AUTOSAR XML (schema 00050)
package /ComponentTypes
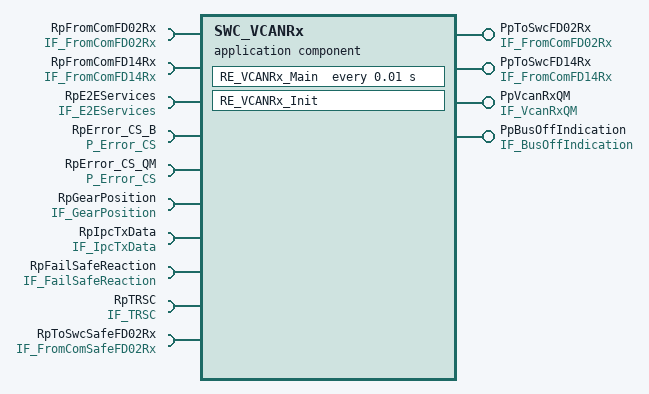
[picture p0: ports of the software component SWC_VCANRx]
  application sw component type SWC_VCANRx
    require port RpFromComFD02Rx: required-interface=IF_FromComFD02Rx
      required-com-specs:
        data-element=Altitude_RMSE_C2, init-value=255
        data-element=Battery_Volt_1, init-value=0
        data-element=BSM_THA_Brk_Resp, enable-update=true, init-value=0
        data-element=CurrentCanNMState_FD01_BCM, init-value=0
        data-element=CurrentCanNMState_FD01_SGW, init-value=0
        data-element=CurrentCanNMState_FD02_BCM, init-value=0
        data-element=CurrentCanNMState_FD02_BSM2, init-value=0
        data-element=CurrentCanNMState_FD02_CADM2, init-value=0
        data-element=CurrentCanNMState_FD02_EPS, init-value=0
        data-element=CurrentCanNMState_FD02_ORC, init-value=0
        data-element=CurrentCanNMState_FD02_SGW, init-value=0
        data-element=CurrentCanNMState_FD02_TRLR_REV, init-value=0
        data-element=CurrentCanNMState_FD03_BCM, init-value=0
        data-element=CurrentCanNMState_FD03_SGW, init-value=0
        data-element=CurrentCanNMState_FD04_BCM, init-value=0
        data-element=CurrentCanNMState_FD08_SGW, init-value=0
        data-element=CurrentCanNMState_FD11_SGW, init-value=0
        data-element=CurrentFailSts_FD01_BCM, init-value=0
        data-element=CurrentFailSts_FD01_SGW, init-value=0
        data-element=CurrentFailSts_FD02_BCM, init-value=0
        data-element=CurrentFailSts_FD02_BSM2, init-value=0
        data-element=CurrentFailSts_FD02_CADM2, init-value=0
        data-element=CurrentFailSts_FD02_EPS, init-value=0
        data-element=CurrentFailSts_FD02_ORC, init-value=0
        data-element=CurrentFailSts_FD02_SGW, init-value=0
        data-element=CurrentFailSts_FD02_TRLR_REV, init-value=0
        data-element=CurrentFailSts_FD03_BCM, init-value=0
        data-element=CurrentFailSts_FD03_SGW, init-value=0
        data-element=CurrentFailSts_FD04_BCM, init-value=0
        data-element=CurrentFailSts_FD08_SGW, init-value=0
        data-element=CurrentFailSts_FD11_SGW, init-value=0
        data-element=DeltaTimestamp_IMUdata, init-value=255
        data-element=DES_FD01_BCM, init-value=0
        data-element=DES_FD01_SGW, init-value=0
        data-element=DES_FD02_BCM, init-value=0
        data-element=DES_FD02_BSM2, init-value=0
        data-element=DES_FD02_CADM2, init-value=0
        data-element=DES_FD02_EPS, init-value=0
        data-element=DES_FD02_ORC, init-value=0
        data-element=DES_FD02_SGW, init-value=0
        data-element=DES_FD02_TRLR_REV, init-value=0
        data-element=DES_FD03_BCM, init-value=0
        data-element=DES_FD03_SGW, init-value=0
        data-element=DES_FD04_BCM, init-value=0
        data-element=DES_FD08_SGW, init-value=0
        data-element=DES_FD11_SGW, init-value=0
        data-element=Digit_{01..11}, init-value=0
        data-element=EOL_FD01_BCM, init-value=0
        data-element=EOL_FD01_SGW, init-value=0
        data-element=EOL_FD02_BCM, init-value=0
        data-element=EOL_FD02_BSM2, init-value=0
        data-element=EOL_FD02_CADM2, init-value=0
        data-element=EOL_FD02_EPS, init-value=0
        data-element=EOL_FD02_ORC, init-value=0
        data-element=EOL_FD02_SGW, init-value=0
        data-element=EOL_FD02_TRLR_REV, init-value=0
        data-element=EOL_FD03_BCM, init-value=0
        data-element=EOL_FD03_SGW, init-value=0
        data-element=EOL_FD04_BCM, init-value=0
        data-element=EOL_FD08_SGW, init-value=0
        data-element=EOL_FD11_SGW, init-value=0
        data-element=EPBSts, enable-update=true, init-value=0
        data-element=GenericFailSts_FD01_BCM, init-value=0
        data-element=GenericFailSts_FD01_SGW, init-value=0
        data-element=GenericFailSts_FD02_BCM, init-value=0
        data-element=GenericFailSts_FD02_BSM2, init-value=0
        data-element=GenericFailSts_FD02_CADM2, init-value=0
        data-element=GenericFailSts_FD02_EPS, init-value=0
        data-element=GenericFailSts_FD02_ORC, init-value=0
        data-element=GenericFailSts_FD02_SGW, init-value=0
        data-element=GenericFailSts_FD02_TRLR_REV, init-value=0
        data-element=GenericFailSts_FD03_BCM, init-value=0
        data-element=GenericFailSts_FD03_SGW, init-value=0
        data-element=GenericFailSts_FD04_BCM, init-value=0
        data-element=GenericFailSts_FD08_SGW, init-value=0
        data-element=GenericFailSts_FD11_SGW, init-value=0
        data-element=Heading_Angle_C2, init-value=65535
        data-element=IgnitionOnCounter, init-value=0
        data-element=LatAcceleration_C2, init-value=4095
        data-element=LatAccelerationOffset_BSM, init-value=255
        data-element=Latitude_RMSE_C2, init-value=255
        data-element=LHF_FastPulseCounter, init-value=0
        data-element=LHF_Spin, init-value=0
        data-element=LHFWheelSpeed, init-value=0
        data-element=LHR_FastPulseCounter, init-value=0
        data-element=LHR_Spin, init-value=0
        data-element=LHRWheelSpeed, init-value=0
        data-element=LongAcceleration_C2, init-value=4095
        data-element=LongAccelerationOffset_BSM, init-value=255
        data-element=Longitude_RMSE_C2, init-value=255
        data-element=OperationalModeSts, init-value=0
        data-element=Pitch_RMSE_C2, init-value=255
        data-element=PitchRate_C2, init-value=4095
        data-element=PreviousCanNMState_FD01_BCM, init-value=0
        data-element=PreviousCanNMState_FD01_SGW, init-value=0
        data-element=PreviousCanNMState_FD02_BCM, init-value=0
        data-element=PreviousCanNMState_FD02_BSM2, init-value=0
        data-element=PreviousCanNMState_FD02_CADM2, init-value=0
        data-element=PreviousCanNMState_FD02_EPS, init-value=0
        data-element=PreviousCanNMState_FD02_ORC, init-value=0
        data-element=PreviousCanNMState_FD02_SGW, init-value=0
        data-element=PreviousCanNMState_FD02_TRLR_REV, init-value=0
        data-element=PreviousCanNMState_FD03_BCM, init-value=0
        data-element=PreviousCanNMState_FD03_SGW, init-value=0
        data-element=PreviousCanNMState_FD04_BCM, init-value=0
        data-element=PreviousCanNMState_FD08_SGW, init-value=0
        data-element=PreviousCanNMState_FD11_SGW, init-value=0
        data-element=REF_VEH_SPEED, init-value=1023
        data-element=RemStActvSts, init-value=0
        data-element=RHF_FastPulseCounter, init-value=0
        data-element=RHF_Spin, init-value=0
        data-element=RHFWheelSpeed, init-value=0
        data-element=RHR_FastPulseCounter, init-value=0
        data-element=RHR_Spin, init-value=0
        data-element=RHRWheelSpeed, init-value=0
        data-element=Roll_RMSE_C2, init-value=255
        data-element=RollRate_C2, init-value=4095
        data-element=SBR1RowDriverSeatSts, enable-update=true, init-value=3
        data-element=StayActiveSource_FD01_BCM, init-value=0
        data-element=StayActiveSource_FD01_SGW, init-value=0
        data-element=StayActiveSource_FD02_BCM, init-value=0
        data-element=StayActiveSource_FD02_BSM2, init-value=0
        data-element=StayActiveSource_FD02_CADM2, init-value=0
        data-element=StayActiveSource_FD02_EPS, init-value=0
        data-element=StayActiveSource_FD02_ORC, init-value=0
        data-element=StayActiveSource_FD02_SGW, init-value=0
        data-element=StayActiveSource_FD02_TRLR_REV, init-value=0
        data-element=StayActiveSource_FD03_BCM, init-value=0
        data-element=StayActiveSource_FD03_SGW, init-value=0
        data-element=StayActiveSource_FD04_BCM, init-value=0
        data-element=StayActiveSource_FD08_SGW, init-value=0
        data-element=StayActiveSource_FD11_SGW, init-value=0
        data-element=TotalOdometer, init-value=0
        data-element=TRSC_CenterBtn_Sts, enable-update=true, init-value=0
        data-element=TRSC_EnableBtn_Sts, enable-update=true, init-value=0
        data-element=TRSC_RawKnob, enable-update=true, init-value=0
        data-element=TurnIndicatorSts, init-value=0
        data-element=VehicleStandStillSts, init-value=1
        data-element=VerticalAcceleration_C2, init-value=4095
        data-element=WakeupSource_FD01_ADCM, init-value=0
        data-element=WakeupSource_FD01_BCM, init-value=0
        data-element=WakeupSource_FD01_SGW, init-value=0
        data-element=WakeupSource_FD02_BCM, init-value=0
        data-element=WakeupSource_FD02_BSM2, init-value=0
        data-element=WakeupSource_FD02_CADM2, init-value=0
        data-element=WakeupSource_FD02_EPS, init-value=0
        data-element=WakeupSource_FD02_ORC, init-value=0
        data-element=WakeupSource_FD02_SGW, init-value=0
        data-element=WakeupSource_FD02_TRLR_REV, init-value=0
        data-element=WakeupSource_FD03_BCM, init-value=0
        data-element=WakeupSource_FD03_SGW, init-value=0
        data-element=WakeupSource_FD04_BCM, init-value=0
        data-element=WakeupSource_FD08_SGW, init-value=0
        data-element=WakeupSource_FD11_SGW, init-value=0
        data-element=YawRate_C2, init-value=4095
        data-element=YawRate_RMSE_C2, init-value=255
    require port RpFromComFD14Rx: required-interface=IF_FromComFD14Rx
      required-com-specs:
        data-element=FD14_Accel_Pedal_Override, init-value=0
        data-element=FD14_DriverReq_AxleTrq_Enabled_BSM, init-value=0
        data-element=FD14_PPPA_TrqEnblRq_Allowed, init-value=0
    provide port PpToSwcFD02Rx: provided-interface=IF_FromComFD02Rx
      provided-com-specs:
        data-element=Altitude_RMSE_C2, init-value=255
        data-element=Battery_Volt_1, init-value=0
        data-element=BSM_THA_Brk_Resp, init-value=0
        data-element=CurrentCanNMState_FD01_BCM, init-value=0
        data-element=CurrentCanNMState_FD01_SGW, init-value=0
        data-element=CurrentCanNMState_FD02_BCM, init-value=0
        data-element=CurrentCanNMState_FD02_BSM2, init-value=0
        data-element=CurrentCanNMState_FD02_CADM2, init-value=0
        data-element=CurrentCanNMState_FD02_EPS, init-value=0
        data-element=CurrentCanNMState_FD02_ORC, init-value=0
        data-element=CurrentCanNMState_FD02_SGW, init-value=0
        data-element=CurrentCanNMState_FD02_TRLR_REV, init-value=0
        data-element=CurrentCanNMState_FD03_BCM, init-value=0
        data-element=CurrentCanNMState_FD03_SGW, init-value=0
        data-element=CurrentCanNMState_FD04_BCM, init-value=0
        data-element=CurrentCanNMState_FD08_SGW, init-value=0
        data-element=CurrentCanNMState_FD11_SGW, init-value=0
        data-element=CurrentFailSts_FD01_BCM, init-value=0
        data-element=CurrentFailSts_FD01_SGW, init-value=0
        data-element=CurrentFailSts_FD02_BCM, init-value=0
        data-element=CurrentFailSts_FD02_BSM2, init-value=0
        data-element=CurrentFailSts_FD02_CADM2, init-value=0
        data-element=CurrentFailSts_FD02_EPS, init-value=0
        data-element=CurrentFailSts_FD02_ORC, init-value=0
        data-element=CurrentFailSts_FD02_SGW, init-value=0
        data-element=CurrentFailSts_FD02_TRLR_REV, init-value=0
        data-element=CurrentFailSts_FD03_BCM, init-value=0
        data-element=CurrentFailSts_FD03_SGW, init-value=0
        data-element=CurrentFailSts_FD04_BCM, init-value=0
        data-element=CurrentFailSts_FD08_SGW, init-value=0
        data-element=CurrentFailSts_FD11_SGW, init-value=0
        data-element=DeltaTimestamp_IMUdata, init-value=255
        data-element=DES_FD01_BCM, init-value=0
        data-element=DES_FD01_SGW, init-value=0
        data-element=DES_FD02_BCM, init-value=0
        data-element=DES_FD02_BSM2, init-value=0
        data-element=DES_FD02_CADM2, init-value=0
        data-element=DES_FD02_EPS, init-value=0
        data-element=DES_FD02_ORC, init-value=0
        data-element=DES_FD02_SGW, init-value=0
        data-element=DES_FD02_TRLR_REV, init-value=0
        data-element=DES_FD03_BCM, init-value=0
        data-element=DES_FD03_SGW, init-value=0
        data-element=DES_FD04_BCM, init-value=0
        data-element=DES_FD08_SGW, init-value=0
        data-element=DES_FD11_SGW, init-value=0
        data-element=Digit_{01..11}, init-value=0
        data-element=EOL_FD01_BCM, init-value=0
        data-element=EOL_FD01_SGW, init-value=0
        data-element=EOL_FD02_BCM, init-value=0
        data-element=EOL_FD02_BSM2, init-value=0
        data-element=EOL_FD02_CADM2, init-value=0
        data-element=EOL_FD02_EPS, init-value=0
        data-element=EOL_FD02_ORC, init-value=0
        data-element=EOL_FD02_SGW, init-value=0
        data-element=EOL_FD02_TRLR_REV, init-value=0
        data-element=EOL_FD03_BCM, init-value=0
        data-element=EOL_FD03_SGW, init-value=0
        data-element=EOL_FD04_BCM, init-value=0
        data-element=EOL_FD08_SGW, init-value=0
        data-element=EOL_FD11_SGW, init-value=0
        data-element=EPBSts, init-value=0
        data-element=GenericFailSts_FD01_BCM, init-value=0
        data-element=GenericFailSts_FD01_SGW, init-value=0
        data-element=GenericFailSts_FD02_BCM, init-value=0
        data-element=GenericFailSts_FD02_BSM2, init-value=0
        data-element=GenericFailSts_FD02_CADM2, init-value=0
        data-element=GenericFailSts_FD02_EPS, init-value=0
        data-element=GenericFailSts_FD02_ORC, init-value=0
        data-element=GenericFailSts_FD02_SGW, init-value=0
        data-element=GenericFailSts_FD02_TRLR_REV, init-value=0
        data-element=GenericFailSts_FD03_BCM, init-value=0
        data-element=GenericFailSts_FD03_SGW, init-value=0
        data-element=GenericFailSts_FD04_BCM, init-value=0
        data-element=GenericFailSts_FD08_SGW, init-value=0
        data-element=GenericFailSts_FD11_SGW, init-value=0
        data-element=Heading_Angle_C2, init-value=65535
        data-element=IgnitionOnCounter, init-value=0
        data-element=LatAcceleration_C2, init-value=4095
        data-element=LatAccelerationOffset_BSM, init-value=255
        data-element=Latitude_RMSE_C2, init-value=255
        data-element=LHF_FastPulseCounter, init-value=0
        data-element=LHF_Spin, init-value=0
        data-element=LHFWheelSpeed, init-value=0
        data-element=LHR_FastPulseCounter, init-value=0
        data-element=LHR_Spin, init-value=0
        data-element=LHRWheelSpeed, init-value=0
        data-element=LongAcceleration_C2, init-value=4095
        data-element=LongAccelerationOffset_BSM, init-value=255
        data-element=Longitude_RMSE_C2, init-value=255
        data-element=OperationalModeSts, init-value=0
        data-element=Pitch_RMSE_C2, init-value=255
        data-element=PitchRate_C2, init-value=4095
        data-element=PreviousCanNMState_FD01_BCM, init-value=0
        data-element=PreviousCanNMState_FD01_SGW, init-value=0
        data-element=PreviousCanNMState_FD02_BCM, init-value=0
        data-element=PreviousCanNMState_FD02_BSM2, init-value=0
        data-element=PreviousCanNMState_FD02_CADM2, init-value=0
        data-element=PreviousCanNMState_FD02_EPS, init-value=0
        data-element=PreviousCanNMState_FD02_ORC, init-value=0
        data-element=PreviousCanNMState_FD02_SGW, init-value=0
        data-element=PreviousCanNMState_FD02_TRLR_REV, init-value=0
        data-element=PreviousCanNMState_FD03_BCM, init-value=0
        data-element=PreviousCanNMState_FD03_SGW, init-value=0
        data-element=PreviousCanNMState_FD04_BCM, init-value=0
        data-element=PreviousCanNMState_FD08_SGW, init-value=0
        data-element=PreviousCanNMState_FD11_SGW, init-value=0
        data-element=REF_VEH_SPEED, init-value=1023
        data-element=RemStActvSts, init-value=0
        data-element=RHF_FastPulseCounter, init-value=0
        data-element=RHF_Spin, init-value=0
        data-element=RHFWheelSpeed, init-value=0
        data-element=RHR_FastPulseCounter, init-value=0
        data-element=RHR_Spin, init-value=0
        data-element=RHRWheelSpeed, init-value=0
        data-element=Roll_RMSE_C2, init-value=255
        data-element=RollRate_C2, init-value=4095
        data-element=SBR1RowDriverSeatSts, init-value=3
        data-element=StayActiveSource_FD01_BCM, init-value=0
        data-element=StayActiveSource_FD01_SGW, init-value=0
        data-element=StayActiveSource_FD02_BCM, init-value=0
        data-element=StayActiveSource_FD02_BSM2, init-value=0
        data-element=StayActiveSource_FD02_CADM2, init-value=0
        data-element=StayActiveSource_FD02_EPS, init-value=0
        data-element=StayActiveSource_FD02_ORC, init-value=0
        data-element=StayActiveSource_FD02_SGW, init-value=0
        data-element=StayActiveSource_FD02_TRLR_REV, init-value=0
        data-element=StayActiveSource_FD03_BCM, init-value=0
        data-element=StayActiveSource_FD03_SGW, init-value=0
        data-element=StayActiveSource_FD04_BCM, init-value=0
        data-element=StayActiveSource_FD08_SGW, init-value=0
        data-element=StayActiveSource_FD11_SGW, init-value=0
        data-element=TotalOdometer, init-value=0
        data-element=TRSC_CenterBtn_Sts, init-value=0
        data-element=TRSC_EnableBtn_Sts, init-value=0
        data-element=TRSC_RawKnob, init-value=0
        data-element=TurnIndicatorSts, init-value=0
        data-element=VehicleStandStillSts, init-value=1
        data-element=VerticalAcceleration_C2, init-value=4095
        data-element=WakeupSource_FD01_ADCM, init-value=0
        data-element=WakeupSource_FD01_BCM, init-value=0
        data-element=WakeupSource_FD01_SGW, init-value=0
        data-element=WakeupSource_FD02_BCM, init-value=0
        data-element=WakeupSource_FD02_BSM2, init-value=0
        data-element=WakeupSource_FD02_CADM2, init-value=0
        data-element=WakeupSource_FD02_EPS, init-value=0
        data-element=WakeupSource_FD02_ORC, init-value=0
        data-element=WakeupSource_FD02_SGW, init-value=0
        data-element=WakeupSource_FD02_TRLR_REV, init-value=0
        data-element=WakeupSource_FD03_BCM, init-value=0
        data-element=WakeupSource_FD03_SGW, init-value=0
        data-element=WakeupSource_FD04_BCM, init-value=0
        data-element=WakeupSource_FD08_SGW, init-value=0
        data-element=WakeupSource_FD11_SGW, init-value=0
        data-element=YawRate_C2, init-value=4095
        data-element=YawRate_RMSE_C2, init-value=255
    provide port PpToSwcFD14Rx: provided-interface=IF_FromComFD14Rx
      provided-com-specs:
        data-element=FD14_Accel_Pedal_Override, init-value=0
        data-element=FD14_DriverReq_AxleTrq_Enabled_BSM, init-value=0
        data-element=FD14_PPPA_TrqEnblRq_Allowed, init-value=0
    6 x require port:
      RpE2EServices: required-com-specs=[ME_E2E_Check, ME_E2E_Protect], required-interface=IF_E2EServices
      RpError_CS_B: client-com-spec=ReportErrorStatus1_0_B, required-interface=P_Error_CS
      RpError_CS_QM: client-com-spec=ReportErrorStatus1_0_QM, required-interface=P_Error_CS
      RpGearPosition: required-interface=IF_GearPosition
        required-com-specs:
          data-element=GearValue, filter=data-filter-type=ALWAYS, init-value=0
          data-element=ShortTermAdjActiveFlag_b, filter=data-filter-type=ALWAYS
      RpIpcTxData: client-com-spec=IPC_Write_v, required-interface=IF_IpcTxData
      RpFailSafeReaction: nonqueued-receiver-com-spec{data-element=State, filter=data-filter-type=ALWAYS, init-value=0}, required-interface=IF_FailSafeReaction
    provide port PpVcanRxQM: nonqueued-sender-com-spec{data-element=ME_VehInp_to_IpcSignals_QM_t, init-value=fields=[{short-label=DataInp_BCM_FD_2, fields=[RemStActvSts:0, TurnIndicatorSts:0]}, {short-label=DataInp_BCM_FD_21, fields=Snow_Plow_Presence:0}, {short-label=DataInp_TRSKM_FD_1, fields=[TRSC_CenterBtn_Sts:0, TRSC_EnableBtn_Sts:0, TRSC_RawKnob:0]}, {short-label=DataInp_FD14_BRAKE_FD_6, fields=FD14_DriverReq_AxleTrq_Enabled_BSM:0}, {short-label=DataInp_ORC_FD_1, fields=SBR1RowDriverSeatSts:0}, {short-label=DataInp_FD14_PT_TORQUE_FD_1, fields=[FD14_Accel_Pedal_Override:0, FD14_PPPA_TrqEnblRq_Allowed:0]}]}, provided-interface=IF_VcanRxQM
    provide port PpBusOffIndication: nonqueued-sender-com-spec{data-element=V_BusOffIndicationFlagRte_u8, init-value=0}, provided-interface=IF_BusOffIndication
    require port RpTRSC: nonqueued-receiver-com-spec=data-element=ME_VehOut_TRSC_t, required-interface=IF_TRSC
    require port RpToSwcSafeFD02Rx: required-interface=IF_FromComSafeFD02Rx
      required-com-specs:
        data-element=YawRate_BSM, filter=data-filter-type=ALWAYS
        data-element=VehicleSpeedVSOSig, filter=data-filter-type=ALWAYS
        data-element=TransmissionSailingSts, filter=data-filter-type=ALWAYS
        data-element=TRANS_ADAS_Inhibit, filter=data-filter-type=ALWAYS
        data-element=TrailerConnectionSts, filter=data-filter-type=ALWAYS
        data-element=TGW_CAMERA_DISP_STAT, filter=data-filter-type=ALWAYS
        data-element=TCASERANGESTATUS, filter=data-filter-type=ALWAYS
        data-element=TargetGear, filter=data-filter-type=ALWAYS
        data-element=SVC_Guidelines, filter=data-filter-type=ALWAYS
        data-element=ShiftLeverPosition, filter=data-filter-type=ALWAYS
        data-element=RHRDoorSts, filter=data-filter-type=ALWAYS
        data-element=RHatchSts, filter=data-filter-type=ALWAYS
        data-element=Rear_Brk_Asst, filter=data-filter-type=ALWAYS
        data-element=PsngrDoorSts, filter=data-filter-type=ALWAYS
        data-element=PAMRequestSts, filter=data-filter-type=ALWAYS
        data-element=PamChimeVolumeRear, filter=data-filter-type=ALWAYS
        data-element=PamChimeVolumeFront, filter=data-filter-type=ALWAYS
        data-element=MRM_STATUS_C2, filter=data-filter-type=ALWAYS
        data-element=LwsSpeed, filter=data-filter-type=ALWAYS
        data-element=LwsAngleType, filter=data-filter-type=ALWAYS
        data-element=LwsAngle, filter=data-filter-type=ALWAYS
        data-element=LongAcceleration_BSM, filter=data-filter-type=ALWAYS
        data-element=LHRDoorSts, filter=data-filter-type=ALWAYS
        data-element=LatAcceleration_BSM, filter=data-filter-type=ALWAYS
        data-element=LanguageSelection, filter=data-filter-type=ALWAYS
        data-element=HAS_Status_C2, filter=data-filter-type=ALWAYS
        data-element=GearEngaged, filter=data-filter-type=ALWAYS
        data-element=Fwrd_Cam_Guidelines, filter=data-filter-type=ALWAYS
        data-element=FT_PAMRequestSts, filter=data-filter-type=ALWAYS
        data-element=ExternalTemperature, filter=data-filter-type=ALWAYS
        data-element=DynamicGrid, filter=data-filter-type=ALWAYS
        data-element=DriverDoorSts, filter=data-filter-type=ALWAYS
        data-element=CmdIgnSts, filter=data-filter-type=ALWAYS
        data-element=Brk_Stat, filter=data-filter-type=ALWAYS
        data-element=Backup_Cam_Delay, filter=data-filter-type=ALWAYS
        data-element=APARequestSts, filter=data-filter-type=ALWAYS
        data-element=Active_Park_Prox_Chime, filter=data-filter-type=ALWAYS
        data-element=Active_Park_Mode, filter=data-filter-type=ALWAYS
        data-element=VIN_MSG, filter=data-filter-type=ALWAYS
        data-element=VIN_DATA, filter=data-filter-type=ALWAYS
        data-element=RR_Lvl_Adj, filter=data-filter-type=ALWAYS
        data-element=RR_Lvl, filter=data-filter-type=ALWAYS
        data-element=RL_Lvl_Adj, filter=data-filter-type=ALWAYS
        data-element=RL_Lvl, filter=data-filter-type=ALWAYS
        data-element=HU_TRSC_EnableBtn_Sts, filter=data-filter-type=ALWAYS
        data-element=GearEngagedForDisplay, filter=data-filter-type=ALWAYS
        data-element=FR_Lvl_Adj, filter=data-filter-type=ALWAYS
        data-element=FR_Lvl, filter=data-filter-type=ALWAYS
        data-element=FL_Lvl_Adj, filter=data-filter-type=ALWAYS
        data-element=FL_Lvl, filter=data-filter-type=ALWAYS
        data-element=ESS_ENG_ST_W, filter=data-filter-type=ALWAYS
        data-element=EngineSts_W, filter=data-filter-type=ALWAYS
        data-element=ECM_TRSC_Resp, filter=data-filter-type=ALWAYS
        data-element=ECM_THA_Resp, filter=data-filter-type=ALWAYS
        data-element=ASCM_SysFail, filter=data-filter-type=ALWAYS
        data-element=ASCM_Stat, filter=data-filter-type=ALWAYS
        data-element=PdlPosActual, filter=data-filter-type=ALWAYS
        data-element=THA_SteeringTouchStat, filter=data-filter-type=ALWAYS
        data-element=EPS_THA_SteeringTorqueResp, filter=data-filter-type=ALWAYS
        data-element=EPS_THA_DriverTorqueOverride, filter=data-filter-type=ALWAYS
        data-element=EPS_SteeringTouq_Resp, filter=data-filter-type=ALWAYS
        data-element=EPS_SteeringTouchStat, filter=data-filter-type=ALWAYS
        data-element=ShiftLeverPositionReq, filter=data-filter-type=ALWAYS
        data-element=Shifter_ADAS_Inhibit, filter=data-filter-type=ALWAYS
        data-element=ITBM_TrlrStat, filter=data-filter-type=ALWAYS
        data-element=CM_TCH_Y_COORD, filter=data-filter-type=ALWAYS
        data-element=CM_TCH_X_COORD, filter=data-filter-type=ALWAYS
        data-element=CM_TCH_STAT, filter=data-filter-type=ALWAYS
        data-element=CameraDisplaySts2, filter=data-filter-type=ALWAYS
    behavior SWC_VCANRx_InternalBehavior: data-type-mapping=[defaultDataTypeMappingSet_CPFS, defaultDataTypeMappingSet_CPFS]
      init event SWC_VCANRx_InitEvent: start-on-event=RE_VCANRx_Init
      timing event TMT_RE_VCANRx_Main: start-on-event=RE_VCANRx_Main, period=0.01
      runnable RE_VCANRx_Init
      runnable RE_VCANRx_Main
        data-receive-point-by-arguments:
          175 x access:
            REC_RpFailSafeReaction_State: accessed-variable=RpFailSafeReaction.State
            REC_RpFromComFD02Rx_Altitude_RMSE_C2: accessed-variable=RpFromComFD02Rx.Altitude_RMSE_C2
            REC_RpFromComFD02Rx_BSM_THA_Brk_Resp: accessed-variable=RpFromComFD02Rx.BSM_THA_Brk_Resp
            REC_RpFromComFD02Rx_Battery_Volt_1: accessed-variable=RpFromComFD02Rx.Battery_Volt_1
            REC_RpFromComFD02Rx_CurrentCanNMState_FD01_BCM: accessed-variable=RpFromComFD02Rx.CurrentCanNMState_FD01_BCM
            REC_RpFromComFD02Rx_CurrentCanNMState_FD01_SGW: accessed-variable=RpFromComFD02Rx.CurrentCanNMState_FD01_SGW
            REC_RpFromComFD02Rx_CurrentCanNMState_FD02_BCM: accessed-variable=RpFromComFD02Rx.CurrentCanNMState_FD02_BCM
            REC_RpFromComFD02Rx_CurrentCanNMState_FD02_BSM2: accessed-variable=RpFromComFD02Rx.CurrentCanNMState_FD02_BSM2
            REC_RpFromComFD02Rx_CurrentCanNMState_FD02_CADM2: accessed-variable=RpFromComFD02Rx.CurrentCanNMState_FD02_CADM2
            REC_RpFromComFD02Rx_CurrentCanNMState_FD02_EPS: accessed-variable=RpFromComFD02Rx.CurrentCanNMState_FD02_EPS
            REC_RpFromComFD02Rx_CurrentCanNMState_FD02_ORC: accessed-variable=RpFromComFD02Rx.CurrentCanNMState_FD02_ORC
            REC_RpFromComFD02Rx_CurrentCanNMState_FD02_SGW: accessed-variable=RpFromComFD02Rx.CurrentCanNMState_FD02_SGW
            REC_RpFromComFD02Rx_CurrentCanNMState_FD02_TRLR_REV: accessed-variable=RpFromComFD02Rx.CurrentCanNMState_FD02_TRLR_REV
            REC_RpFromComFD02Rx_CurrentCanNMState_FD03_BCM: accessed-variable=RpFromComFD02Rx.CurrentCanNMState_FD03_BCM
            REC_RpFromComFD02Rx_CurrentCanNMState_FD03_SGW: accessed-variable=RpFromComFD02Rx.CurrentCanNMState_FD03_SGW
            REC_RpFromComFD02Rx_CurrentCanNMState_FD04_BCM: accessed-variable=RpFromComFD02Rx.CurrentCanNMState_FD04_BCM
            REC_RpFromComFD02Rx_CurrentCanNMState_FD08_SGW: accessed-variable=RpFromComFD02Rx.CurrentCanNMState_FD08_SGW
            REC_RpFromComFD02Rx_CurrentCanNMState_FD11_SGW: accessed-variable=RpFromComFD02Rx.CurrentCanNMState_FD11_SGW
            REC_RpFromComFD02Rx_CurrentFailSts_FD01_BCM: accessed-variable=RpFromComFD02Rx.CurrentFailSts_FD01_BCM
            REC_RpFromComFD02Rx_CurrentFailSts_FD01_SGW: accessed-variable=RpFromComFD02Rx.CurrentFailSts_FD01_SGW
            REC_RpFromComFD02Rx_CurrentFailSts_FD02_BCM: accessed-variable=RpFromComFD02Rx.CurrentFailSts_FD02_BCM
            REC_RpFromComFD02Rx_CurrentFailSts_FD02_BSM2: accessed-variable=RpFromComFD02Rx.CurrentFailSts_FD02_BSM2
            REC_RpFromComFD02Rx_CurrentFailSts_FD02_CADM2: accessed-variable=RpFromComFD02Rx.CurrentFailSts_FD02_CADM2
            REC_RpFromComFD02Rx_CurrentFailSts_FD02_EPS: accessed-variable=RpFromComFD02Rx.CurrentFailSts_FD02_EPS
            REC_RpFromComFD02Rx_CurrentFailSts_FD02_ORC: accessed-variable=RpFromComFD02Rx.CurrentFailSts_FD02_ORC
            REC_RpFromComFD02Rx_CurrentFailSts_FD02_SGW: accessed-variable=RpFromComFD02Rx.CurrentFailSts_FD02_SGW
            REC_RpFromComFD02Rx_CurrentFailSts_FD02_TRLR_REV: accessed-variable=RpFromComFD02Rx.CurrentFailSts_FD02_TRLR_REV
            REC_RpFromComFD02Rx_CurrentFailSts_FD03_BCM: accessed-variable=RpFromComFD02Rx.CurrentFailSts_FD03_BCM
            REC_RpFromComFD02Rx_CurrentFailSts_FD03_SGW: accessed-variable=RpFromComFD02Rx.CurrentFailSts_FD03_SGW
            REC_RpFromComFD02Rx_CurrentFailSts_FD04_BCM: accessed-variable=RpFromComFD02Rx.CurrentFailSts_FD04_BCM
            REC_RpFromComFD02Rx_CurrentFailSts_FD08_SGW: accessed-variable=RpFromComFD02Rx.CurrentFailSts_FD08_SGW
            REC_RpFromComFD02Rx_CurrentFailSts_FD11_SGW: accessed-variable=RpFromComFD02Rx.CurrentFailSts_FD11_SGW
            REC_RpFromComFD02Rx_DES_FD01_BCM: accessed-variable=RpFromComFD02Rx.DES_FD01_BCM
            REC_RpFromComFD02Rx_DES_FD01_SGW: accessed-variable=RpFromComFD02Rx.DES_FD01_SGW
            REC_RpFromComFD02Rx_DES_FD02_BCM: accessed-variable=RpFromComFD02Rx.DES_FD02_BCM
            REC_RpFromComFD02Rx_DES_FD02_BSM2: accessed-variable=RpFromComFD02Rx.DES_FD02_BSM2
            REC_RpFromComFD02Rx_DES_FD02_CADM2: accessed-variable=RpFromComFD02Rx.DES_FD02_CADM2
            REC_RpFromComFD02Rx_DES_FD02_EPS: accessed-variable=RpFromComFD02Rx.DES_FD02_EPS
            REC_RpFromComFD02Rx_DES_FD02_ORC: accessed-variable=RpFromComFD02Rx.DES_FD02_ORC
            REC_RpFromComFD02Rx_DES_FD02_SGW: accessed-variable=RpFromComFD02Rx.DES_FD02_SGW
            REC_RpFromComFD02Rx_DES_FD02_TRLR_REV: accessed-variable=RpFromComFD02Rx.DES_FD02_TRLR_REV
            REC_RpFromComFD02Rx_DES_FD03_BCM: accessed-variable=RpFromComFD02Rx.DES_FD03_BCM
            REC_RpFromComFD02Rx_DES_FD03_SGW: accessed-variable=RpFromComFD02Rx.DES_FD03_SGW
            REC_RpFromComFD02Rx_DES_FD04_BCM: accessed-variable=RpFromComFD02Rx.DES_FD04_BCM
            REC_RpFromComFD02Rx_DES_FD08_SGW: accessed-variable=RpFromComFD02Rx.DES_FD08_SGW
            REC_RpFromComFD02Rx_DES_FD11_SGW: accessed-variable=RpFromComFD02Rx.DES_FD11_SGW
            REC_RpFromComFD02Rx_DeltaTimestamp_IMUdata: accessed-variable=RpFromComFD02Rx.DeltaTimestamp_IMUdata
            REC_RpFromComFD02Rx_Digit_{01..11}: accessed-variable=RpFromComFD02Rx.Digit_{01..11}
            REC_RpFromComFD02Rx_EOL_FD01_BCM: accessed-variable=RpFromComFD02Rx.EOL_FD01_BCM
            REC_RpFromComFD02Rx_EOL_FD01_SGW: accessed-variable=RpFromComFD02Rx.EOL_FD01_SGW
            REC_RpFromComFD02Rx_EOL_FD02_BCM: accessed-variable=RpFromComFD02Rx.EOL_FD02_BCM
            REC_RpFromComFD02Rx_EOL_FD02_BSM2: accessed-variable=RpFromComFD02Rx.EOL_FD02_BSM2
            REC_RpFromComFD02Rx_EOL_FD02_CADM2: accessed-variable=RpFromComFD02Rx.EOL_FD02_CADM2
            REC_RpFromComFD02Rx_EOL_FD02_EPS: accessed-variable=RpFromComFD02Rx.EOL_FD02_EPS
            REC_RpFromComFD02Rx_EOL_FD02_ORC: accessed-variable=RpFromComFD02Rx.EOL_FD02_ORC
            REC_RpFromComFD02Rx_EOL_FD02_SGW: accessed-variable=RpFromComFD02Rx.EOL_FD02_SGW
            REC_RpFromComFD02Rx_EOL_FD02_TRLR_REV: accessed-variable=RpFromComFD02Rx.EOL_FD02_TRLR_REV
            REC_RpFromComFD02Rx_EOL_FD03_BCM: accessed-variable=RpFromComFD02Rx.EOL_FD03_BCM
            REC_RpFromComFD02Rx_EOL_FD03_SGW: accessed-variable=RpFromComFD02Rx.EOL_FD03_SGW
            REC_RpFromComFD02Rx_EOL_FD04_BCM: accessed-variable=RpFromComFD02Rx.EOL_FD04_BCM
            REC_RpFromComFD02Rx_EOL_FD08_SGW: accessed-variable=RpFromComFD02Rx.EOL_FD08_SGW
            REC_RpFromComFD02Rx_EOL_FD11_SGW: accessed-variable=RpFromComFD02Rx.EOL_FD11_SGW
            REC_RpFromComFD02Rx_EPBSts: accessed-variable=RpFromComFD02Rx.EPBSts
            REC_RpFromComFD02Rx_GenericFailSts_FD01_BCM: accessed-variable=RpFromComFD02Rx.GenericFailSts_FD01_BCM
            REC_RpFromComFD02Rx_GenericFailSts_FD01_SGW: accessed-variable=RpFromComFD02Rx.GenericFailSts_FD01_SGW
            REC_RpFromComFD02Rx_GenericFailSts_FD02_BCM: accessed-variable=RpFromComFD02Rx.GenericFailSts_FD02_BCM
            REC_RpFromComFD02Rx_GenericFailSts_FD02_BSM2: accessed-variable=RpFromComFD02Rx.GenericFailSts_FD02_BSM2
            REC_RpFromComFD02Rx_GenericFailSts_FD02_CADM2: accessed-variable=RpFromComFD02Rx.GenericFailSts_FD02_CADM2
            REC_RpFromComFD02Rx_GenericFailSts_FD02_EPS: accessed-variable=RpFromComFD02Rx.GenericFailSts_FD02_EPS
            REC_RpFromComFD02Rx_GenericFailSts_FD02_ORC: accessed-variable=RpFromComFD02Rx.GenericFailSts_FD02_ORC
            REC_RpFromComFD02Rx_GenericFailSts_FD02_SGW: accessed-variable=RpFromComFD02Rx.GenericFailSts_FD02_SGW
            REC_RpFromComFD02Rx_GenericFailSts_FD02_TRLR_REV: accessed-variable=RpFromComFD02Rx.GenericFailSts_FD02_TRLR_REV
            REC_RpFromComFD02Rx_GenericFailSts_FD03_BCM: accessed-variable=RpFromComFD02Rx.GenericFailSts_FD03_BCM
            REC_RpFromComFD02Rx_GenericFailSts_FD03_SGW: accessed-variable=RpFromComFD02Rx.GenericFailSts_FD03_SGW
            REC_RpFromComFD02Rx_GenericFailSts_FD04_BCM: accessed-variable=RpFromComFD02Rx.GenericFailSts_FD04_BCM
            REC_RpFromComFD02Rx_GenericFailSts_FD08_SGW: accessed-variable=RpFromComFD02Rx.GenericFailSts_FD08_SGW
            REC_RpFromComFD02Rx_GenericFailSts_FD11_SGW: accessed-variable=RpFromComFD02Rx.GenericFailSts_FD11_SGW
            REC_RpFromComFD02Rx_Heading_Angle_C2: accessed-variable=RpFromComFD02Rx.Heading_Angle_C2
            REC_RpFromComFD02Rx_IgnitionOnCounter: accessed-variable=RpFromComFD02Rx.IgnitionOnCounter
            REC_RpFromComFD02Rx_LHFWheelSpeed: accessed-variable=RpFromComFD02Rx.LHFWheelSpeed
            REC_RpFromComFD02Rx_LHF_FastPulseCounter: accessed-variable=RpFromComFD02Rx.LHF_FastPulseCounter
            REC_RpFromComFD02Rx_LHF_Spin: accessed-variable=RpFromComFD02Rx.LHF_Spin
            REC_RpFromComFD02Rx_LHRWheelSpeed: accessed-variable=RpFromComFD02Rx.LHRWheelSpeed
            REC_RpFromComFD02Rx_LHR_FastPulseCounter: accessed-variable=RpFromComFD02Rx.LHR_FastPulseCounter
            REC_RpFromComFD02Rx_LHR_Spin: accessed-variable=RpFromComFD02Rx.LHR_Spin
            REC_RpFromComFD02Rx_LatAccelerationOffset_BSM: accessed-variable=RpFromComFD02Rx.LatAccelerationOffset_BSM
            REC_RpFromComFD02Rx_LatAcceleration_C2: accessed-variable=RpFromComFD02Rx.LatAcceleration_C2
            REC_RpFromComFD02Rx_Latitude_RMSE_C2: accessed-variable=RpFromComFD02Rx.Latitude_RMSE_C2
            REC_RpFromComFD02Rx_LongAccelerationOffset_BSM: accessed-variable=RpFromComFD02Rx.LongAccelerationOffset_BSM
            REC_RpFromComFD02Rx_LongAcceleration_C2: accessed-variable=RpFromComFD02Rx.LongAcceleration_C2
            REC_RpFromComFD02Rx_Longitude_RMSE_C2: accessed-variable=RpFromComFD02Rx.Longitude_RMSE_C2
            REC_RpFromComFD02Rx_OperationalModeSts: accessed-variable=RpFromComFD02Rx.OperationalModeSts
            REC_RpFromComFD02Rx_PitchRate_C2: accessed-variable=RpFromComFD02Rx.PitchRate_C2
            REC_RpFromComFD02Rx_Pitch_RMSE_C2: accessed-variable=RpFromComFD02Rx.Pitch_RMSE_C2
            REC_RpFromComFD02Rx_PreviousCanNMState_FD01_BCM: accessed-variable=RpFromComFD02Rx.PreviousCanNMState_FD01_BCM
            REC_RpFromComFD02Rx_PreviousCanNMState_FD01_SGW: accessed-variable=RpFromComFD02Rx.PreviousCanNMState_FD01_SGW
            REC_RpFromComFD02Rx_PreviousCanNMState_FD02_BCM: accessed-variable=RpFromComFD02Rx.PreviousCanNMState_FD02_BCM
            REC_RpFromComFD02Rx_PreviousCanNMState_FD02_BSM2: accessed-variable=RpFromComFD02Rx.PreviousCanNMState_FD02_BSM2
            REC_RpFromComFD02Rx_PreviousCanNMState_FD02_CADM2: accessed-variable=RpFromComFD02Rx.PreviousCanNMState_FD02_CADM2
            REC_RpFromComFD02Rx_PreviousCanNMState_FD02_EPS: accessed-variable=RpFromComFD02Rx.PreviousCanNMState_FD02_EPS
            REC_RpFromComFD02Rx_PreviousCanNMState_FD02_ORC: accessed-variable=RpFromComFD02Rx.PreviousCanNMState_FD02_ORC
            REC_RpFromComFD02Rx_PreviousCanNMState_FD02_SGW: accessed-variable=RpFromComFD02Rx.PreviousCanNMState_FD02_SGW
            REC_RpFromComFD02Rx_PreviousCanNMState_FD02_TRLR_REV: accessed-variable=RpFromComFD02Rx.PreviousCanNMState_FD02_TRLR_REV
            REC_RpFromComFD02Rx_PreviousCanNMState_FD03_BCM: accessed-variable=RpFromComFD02Rx.PreviousCanNMState_FD03_BCM
            REC_RpFromComFD02Rx_PreviousCanNMState_FD03_SGW: accessed-variable=RpFromComFD02Rx.PreviousCanNMState_FD03_SGW
            REC_RpFromComFD02Rx_PreviousCanNMState_FD04_BCM: accessed-variable=RpFromComFD02Rx.PreviousCanNMState_FD04_BCM
            REC_RpFromComFD02Rx_PreviousCanNMState_FD08_SGW: accessed-variable=RpFromComFD02Rx.PreviousCanNMState_FD08_SGW
            REC_RpFromComFD02Rx_PreviousCanNMState_FD11_SGW: accessed-variable=RpFromComFD02Rx.PreviousCanNMState_FD11_SGW
            REC_RpFromComFD02Rx_REF_VEH_SPEED: accessed-variable=RpFromComFD02Rx.REF_VEH_SPEED
            REC_RpFromComFD02Rx_RHFWheelSpeed: accessed-variable=RpFromComFD02Rx.RHFWheelSpeed
            REC_RpFromComFD02Rx_RHF_FastPulseCounter: accessed-variable=RpFromComFD02Rx.RHF_FastPulseCounter
            REC_RpFromComFD02Rx_RHF_Spin: accessed-variable=RpFromComFD02Rx.RHF_Spin
            REC_RpFromComFD02Rx_RHRWheelSpeed: accessed-variable=RpFromComFD02Rx.RHRWheelSpeed
            REC_RpFromComFD02Rx_RHR_FastPulseCounter: accessed-variable=RpFromComFD02Rx.RHR_FastPulseCounter
            REC_RpFromComFD02Rx_RHR_Spin: accessed-variable=RpFromComFD02Rx.RHR_Spin
            REC_RpFromComFD02Rx_RemStActvSts: accessed-variable=RpFromComFD02Rx.RemStActvSts
            REC_RpFromComFD02Rx_RollRate_C2: accessed-variable=RpFromComFD02Rx.RollRate_C2
            REC_RpFromComFD02Rx_Roll_RMSE_C2: accessed-variable=RpFromComFD02Rx.Roll_RMSE_C2
            REC_RpFromComFD02Rx_SBR1RowDriverSeatSts: accessed-variable=RpFromComFD02Rx.SBR1RowDriverSeatSts
            REC_RpFromComFD02Rx_StayActiveSource_FD01_BCM: accessed-variable=RpFromComFD02Rx.StayActiveSource_FD01_BCM
            REC_RpFromComFD02Rx_StayActiveSource_FD01_SGW: accessed-variable=RpFromComFD02Rx.StayActiveSource_FD01_SGW
            REC_RpFromComFD02Rx_StayActiveSource_FD02_BCM: accessed-variable=RpFromComFD02Rx.StayActiveSource_FD02_BCM
            REC_RpFromComFD02Rx_StayActiveSource_FD02_BSM2: accessed-variable=RpFromComFD02Rx.StayActiveSource_FD02_BSM2
            REC_RpFromComFD02Rx_StayActiveSource_FD02_CADM2: accessed-variable=RpFromComFD02Rx.StayActiveSource_FD02_CADM2
            REC_RpFromComFD02Rx_StayActiveSource_FD02_EPS: accessed-variable=RpFromComFD02Rx.StayActiveSource_FD02_EPS
            REC_RpFromComFD02Rx_StayActiveSource_FD02_ORC: accessed-variable=RpFromComFD02Rx.StayActiveSource_FD02_ORC
            REC_RpFromComFD02Rx_StayActiveSource_FD02_SGW: accessed-variable=RpFromComFD02Rx.StayActiveSource_FD02_SGW
            REC_RpFromComFD02Rx_StayActiveSource_FD02_TRLR_REV: accessed-variable=RpFromComFD02Rx.StayActiveSource_FD02_TRLR_REV
            REC_RpFromComFD02Rx_StayActiveSource_FD03_BCM: accessed-variable=RpFromComFD02Rx.StayActiveSource_FD03_BCM
            REC_RpFromComFD02Rx_StayActiveSource_FD03_SGW: accessed-variable=RpFromComFD02Rx.StayActiveSource_FD03_SGW
            REC_RpFromComFD02Rx_StayActiveSource_FD04_BCM: accessed-variable=RpFromComFD02Rx.StayActiveSource_FD04_BCM
            REC_RpFromComFD02Rx_StayActiveSource_FD08_SGW: accessed-variable=RpFromComFD02Rx.StayActiveSource_FD08_SGW
            REC_RpFromComFD02Rx_StayActiveSource_FD11_SGW: accessed-variable=RpFromComFD02Rx.StayActiveSource_FD11_SGW
            REC_RpFromComFD02Rx_TRSC_CenterBtn_Sts: accessed-variable=RpFromComFD02Rx.TRSC_CenterBtn_Sts
            REC_RpFromComFD02Rx_TRSC_EnableBtn_Sts: accessed-variable=RpFromComFD02Rx.TRSC_EnableBtn_Sts
            REC_RpFromComFD02Rx_TRSC_RawKnob: accessed-variable=RpFromComFD02Rx.TRSC_RawKnob
            REC_RpFromComFD02Rx_TotalOdometer: accessed-variable=RpFromComFD02Rx.TotalOdometer
            REC_RpFromComFD02Rx_TurnIndicatorSts: accessed-variable=RpFromComFD02Rx.TurnIndicatorSts
            REC_RpFromComFD02Rx_VehicleStandStillSts: accessed-variable=RpFromComFD02Rx.VehicleStandStillSts
            REC_RpFromComFD02Rx_VerticalAcceleration_C2: accessed-variable=RpFromComFD02Rx.VerticalAcceleration_C2
            REC_RpFromComFD02Rx_WakeupSource_FD01_ADCM: accessed-variable=RpFromComFD02Rx.WakeupSource_FD01_ADCM
            REC_RpFromComFD02Rx_WakeupSource_FD01_BCM: accessed-variable=RpFromComFD02Rx.WakeupSource_FD01_BCM
            REC_RpFromComFD02Rx_WakeupSource_FD01_SGW: accessed-variable=RpFromComFD02Rx.WakeupSource_FD01_SGW
            REC_RpFromComFD02Rx_WakeupSource_FD02_BCM: accessed-variable=RpFromComFD02Rx.WakeupSource_FD02_BCM
            REC_RpFromComFD02Rx_WakeupSource_FD02_BSM2: accessed-variable=RpFromComFD02Rx.WakeupSource_FD02_BSM2
            REC_RpFromComFD02Rx_WakeupSource_FD02_CADM2: accessed-variable=RpFromComFD02Rx.WakeupSource_FD02_CADM2
            REC_RpFromComFD02Rx_WakeupSource_FD02_EPS: accessed-variable=RpFromComFD02Rx.WakeupSource_FD02_EPS
            REC_RpFromComFD02Rx_WakeupSource_FD02_ORC: accessed-variable=RpFromComFD02Rx.WakeupSource_FD02_ORC
            REC_RpFromComFD02Rx_WakeupSource_FD02_SGW: accessed-variable=RpFromComFD02Rx.WakeupSource_FD02_SGW
            REC_RpFromComFD02Rx_WakeupSource_FD02_TRLR_REV: accessed-variable=RpFromComFD02Rx.WakeupSource_FD02_TRLR_REV
            REC_RpFromComFD02Rx_WakeupSource_FD03_BCM: accessed-variable=RpFromComFD02Rx.WakeupSource_FD03_BCM
            REC_RpFromComFD02Rx_WakeupSource_FD03_SGW: accessed-variable=RpFromComFD02Rx.WakeupSource_FD03_SGW
            REC_RpFromComFD02Rx_WakeupSource_FD04_BCM: accessed-variable=RpFromComFD02Rx.WakeupSource_FD04_BCM
            REC_RpFromComFD02Rx_WakeupSource_FD08_SGW: accessed-variable=RpFromComFD02Rx.WakeupSource_FD08_SGW
            REC_RpFromComFD02Rx_WakeupSource_FD11_SGW: accessed-variable=RpFromComFD02Rx.WakeupSource_FD11_SGW
            REC_RpFromComFD02Rx_YawRate_C2: accessed-variable=RpFromComFD02Rx.YawRate_C2
            REC_RpFromComFD02Rx_YawRate_RMSE_C2: accessed-variable=RpFromComFD02Rx.YawRate_RMSE_C2
            REC_RpFromComFD14Rx_FD14_Accel_Pedal_Override: accessed-variable=RpFromComFD14Rx.FD14_Accel_Pedal_Override
            REC_RpFromComFD14Rx_FD14_DriverReq_AxleTrq_Enabled_BSM: accessed-variable=RpFromComFD14Rx.FD14_DriverReq_AxleTrq_Enabled_BSM
            REC_RpFromComFD14Rx_FD14_PPPA_TrqEnblRq_Allowed: accessed-variable=RpFromComFD14Rx.FD14_PPPA_TrqEnblRq_Allowed
            REC_RpGearPosition_GearValue: accessed-variable=RpGearPosition.GearValue
            REC_RpGearPosition_ShortTermAdjActiveFlag_b: accessed-variable=RpGearPosition.ShortTermAdjActiveFlag_b
            REC_RpTRSC_ME_VehOut_TRSC_t: accessed-variable=RpTRSC.ME_VehOut_TRSC_t
            REC_RpToSwcSafeFD02Rx_ITBM_TrlrStat: accessed-variable=RpToSwcSafeFD02Rx.ITBM_TrlrStat
            REC_RpToSwcSafeFD02Rx_TrailerConnectionSts: accessed-variable=RpToSwcSafeFD02Rx.TrailerConnectionSts
        data-send-points:
          171 x access:
            SEND_PpToSwcFD02Rx_Altitude_RMSE_C2: accessed-variable=PpToSwcFD02Rx.Altitude_RMSE_C2
            SEND_PpToSwcFD02Rx_BSM_THA_Brk_Resp: accessed-variable=PpToSwcFD02Rx.BSM_THA_Brk_Resp
            SEND_PpToSwcFD02Rx_Battery_Volt_1: accessed-variable=PpToSwcFD02Rx.Battery_Volt_1
            SEND_PpToSwcFD02Rx_CurrentCanNMState_FD01_BCM: accessed-variable=PpToSwcFD02Rx.CurrentCanNMState_FD01_BCM
            SEND_PpToSwcFD02Rx_CurrentCanNMState_FD01_SGW: accessed-variable=PpToSwcFD02Rx.CurrentCanNMState_FD01_SGW
            SEND_PpToSwcFD02Rx_CurrentCanNMState_FD02_BCM: accessed-variable=PpToSwcFD02Rx.CurrentCanNMState_FD02_BCM
            SEND_PpToSwcFD02Rx_CurrentCanNMState_FD02_BSM2: accessed-variable=PpToSwcFD02Rx.CurrentCanNMState_FD02_BSM2
            SEND_PpToSwcFD02Rx_CurrentCanNMState_FD02_CADM2: accessed-variable=PpToSwcFD02Rx.CurrentCanNMState_FD02_CADM2
            SEND_PpToSwcFD02Rx_CurrentCanNMState_FD02_EPS: accessed-variable=PpToSwcFD02Rx.CurrentCanNMState_FD02_EPS
            SEND_PpToSwcFD02Rx_CurrentCanNMState_FD02_ORC: accessed-variable=PpToSwcFD02Rx.CurrentCanNMState_FD02_ORC
            SEND_PpToSwcFD02Rx_CurrentCanNMState_FD02_SGW: accessed-variable=PpToSwcFD02Rx.CurrentCanNMState_FD02_SGW
            SEND_PpToSwcFD02Rx_CurrentCanNMState_FD02_TRLR_REV: accessed-variable=PpToSwcFD02Rx.CurrentCanNMState_FD02_TRLR_REV
            SEND_PpToSwcFD02Rx_CurrentCanNMState_FD03_BCM: accessed-variable=PpToSwcFD02Rx.CurrentCanNMState_FD03_BCM
            SEND_PpToSwcFD02Rx_CurrentCanNMState_FD03_SGW: accessed-variable=PpToSwcFD02Rx.CurrentCanNMState_FD03_SGW
            SEND_PpToSwcFD02Rx_CurrentCanNMState_FD04_BCM: accessed-variable=PpToSwcFD02Rx.CurrentCanNMState_FD04_BCM
            SEND_PpToSwcFD02Rx_CurrentCanNMState_FD08_SGW: accessed-variable=PpToSwcFD02Rx.CurrentCanNMState_FD08_SGW
            SEND_PpToSwcFD02Rx_CurrentCanNMState_FD11_SGW: accessed-variable=PpToSwcFD02Rx.CurrentCanNMState_FD11_SGW
            SEND_PpToSwcFD02Rx_CurrentFailSts_FD01_BCM: accessed-variable=PpToSwcFD02Rx.CurrentFailSts_FD01_BCM
            SEND_PpToSwcFD02Rx_CurrentFailSts_FD01_SGW: accessed-variable=PpToSwcFD02Rx.CurrentFailSts_FD01_SGW
            SEND_PpToSwcFD02Rx_CurrentFailSts_FD02_BCM: accessed-variable=PpToSwcFD02Rx.CurrentFailSts_FD02_BCM
            SEND_PpToSwcFD02Rx_CurrentFailSts_FD02_BSM2: accessed-variable=PpToSwcFD02Rx.CurrentFailSts_FD02_BSM2
            SEND_PpToSwcFD02Rx_CurrentFailSts_FD02_CADM2: accessed-variable=PpToSwcFD02Rx.CurrentFailSts_FD02_CADM2
            SEND_PpToSwcFD02Rx_CurrentFailSts_FD02_EPS: accessed-variable=PpToSwcFD02Rx.CurrentFailSts_FD02_EPS
            SEND_PpToSwcFD02Rx_CurrentFailSts_FD02_ORC: accessed-variable=PpToSwcFD02Rx.CurrentFailSts_FD02_ORC
            SEND_PpToSwcFD02Rx_CurrentFailSts_FD02_SGW: accessed-variable=PpToSwcFD02Rx.CurrentFailSts_FD02_SGW
            SEND_PpToSwcFD02Rx_CurrentFailSts_FD02_TRLR_REV: accessed-variable=PpToSwcFD02Rx.CurrentFailSts_FD02_TRLR_REV
            SEND_PpToSwcFD02Rx_CurrentFailSts_FD03_BCM: accessed-variable=PpToSwcFD02Rx.CurrentFailSts_FD03_BCM
            SEND_PpToSwcFD02Rx_CurrentFailSts_FD03_SGW: accessed-variable=PpToSwcFD02Rx.CurrentFailSts_FD03_SGW
            SEND_PpToSwcFD02Rx_CurrentFailSts_FD04_BCM: accessed-variable=PpToSwcFD02Rx.CurrentFailSts_FD04_BCM
            SEND_PpToSwcFD02Rx_CurrentFailSts_FD08_SGW: accessed-variable=PpToSwcFD02Rx.CurrentFailSts_FD08_SGW
            SEND_PpToSwcFD02Rx_CurrentFailSts_FD11_SGW: accessed-variable=PpToSwcFD02Rx.CurrentFailSts_FD11_SGW
            SEND_PpToSwcFD02Rx_DES_FD01_BCM: accessed-variable=PpToSwcFD02Rx.DES_FD01_BCM
            SEND_PpToSwcFD02Rx_DES_FD01_SGW: accessed-variable=PpToSwcFD02Rx.DES_FD01_SGW
            SEND_PpToSwcFD02Rx_DES_FD02_BCM: accessed-variable=PpToSwcFD02Rx.DES_FD02_BCM
            SEND_PpToSwcFD02Rx_DES_FD02_BSM2: accessed-variable=PpToSwcFD02Rx.DES_FD02_BSM2
            SEND_PpToSwcFD02Rx_DES_FD02_CADM2: accessed-variable=PpToSwcFD02Rx.DES_FD02_CADM2
            SEND_PpToSwcFD02Rx_DES_FD02_EPS: accessed-variable=PpToSwcFD02Rx.DES_FD02_EPS
            SEND_PpToSwcFD02Rx_DES_FD02_ORC: accessed-variable=PpToSwcFD02Rx.DES_FD02_ORC
            SEND_PpToSwcFD02Rx_DES_FD02_SGW: accessed-variable=PpToSwcFD02Rx.DES_FD02_SGW
            SEND_PpToSwcFD02Rx_DES_FD02_TRLR_REV: accessed-variable=PpToSwcFD02Rx.DES_FD02_TRLR_REV
            SEND_PpToSwcFD02Rx_DES_FD03_BCM: accessed-variable=PpToSwcFD02Rx.DES_FD03_BCM
            SEND_PpToSwcFD02Rx_DES_FD03_SGW: accessed-variable=PpToSwcFD02Rx.DES_FD03_SGW
            SEND_PpToSwcFD02Rx_DES_FD04_BCM: accessed-variable=PpToSwcFD02Rx.DES_FD04_BCM
            SEND_PpToSwcFD02Rx_DES_FD08_SGW: accessed-variable=PpToSwcFD02Rx.DES_FD08_SGW
            SEND_PpToSwcFD02Rx_DES_FD11_SGW: accessed-variable=PpToSwcFD02Rx.DES_FD11_SGW
            SEND_PpToSwcFD02Rx_DeltaTimestamp_IMUdata: accessed-variable=PpToSwcFD02Rx.DeltaTimestamp_IMUdata
            SEND_PpToSwcFD02Rx_Digit_{01..11}: accessed-variable=PpToSwcFD02Rx.Digit_{01..11}
            SEND_PpToSwcFD02Rx_EOL_FD01_BCM: accessed-variable=PpToSwcFD02Rx.EOL_FD01_BCM
            SEND_PpToSwcFD02Rx_EOL_FD01_SGW: accessed-variable=PpToSwcFD02Rx.EOL_FD01_SGW
            SEND_PpToSwcFD02Rx_EOL_FD02_BCM: accessed-variable=PpToSwcFD02Rx.EOL_FD02_BCM
            SEND_PpToSwcFD02Rx_EOL_FD02_BSM2: accessed-variable=PpToSwcFD02Rx.EOL_FD02_BSM2
            SEND_PpToSwcFD02Rx_EOL_FD02_CADM2: accessed-variable=PpToSwcFD02Rx.EOL_FD02_CADM2
            SEND_PpToSwcFD02Rx_EOL_FD02_EPS: accessed-variable=PpToSwcFD02Rx.EOL_FD02_EPS
            SEND_PpToSwcFD02Rx_EOL_FD02_ORC: accessed-variable=PpToSwcFD02Rx.EOL_FD02_ORC
            SEND_PpToSwcFD02Rx_EOL_FD02_SGW: accessed-variable=PpToSwcFD02Rx.EOL_FD02_SGW
            SEND_PpToSwcFD02Rx_EOL_FD02_TRLR_REV: accessed-variable=PpToSwcFD02Rx.EOL_FD02_TRLR_REV
            SEND_PpToSwcFD02Rx_EOL_FD03_BCM: accessed-variable=PpToSwcFD02Rx.EOL_FD03_BCM
            SEND_PpToSwcFD02Rx_EOL_FD03_SGW: accessed-variable=PpToSwcFD02Rx.EOL_FD03_SGW
            SEND_PpToSwcFD02Rx_EOL_FD04_BCM: accessed-variable=PpToSwcFD02Rx.EOL_FD04_BCM
            SEND_PpToSwcFD02Rx_EOL_FD08_SGW: accessed-variable=PpToSwcFD02Rx.EOL_FD08_SGW
            SEND_PpToSwcFD02Rx_EOL_FD11_SGW: accessed-variable=PpToSwcFD02Rx.EOL_FD11_SGW
            SEND_PpToSwcFD02Rx_EPBSts: accessed-variable=PpToSwcFD02Rx.EPBSts
            SEND_PpToSwcFD02Rx_GenericFailSts_FD01_BCM: accessed-variable=PpToSwcFD02Rx.GenericFailSts_FD01_BCM
            SEND_PpToSwcFD02Rx_GenericFailSts_FD01_SGW: accessed-variable=PpToSwcFD02Rx.GenericFailSts_FD01_SGW
            SEND_PpToSwcFD02Rx_GenericFailSts_FD02_BCM: accessed-variable=PpToSwcFD02Rx.GenericFailSts_FD02_BCM
            SEND_PpToSwcFD02Rx_GenericFailSts_FD02_BSM2: accessed-variable=PpToSwcFD02Rx.GenericFailSts_FD02_BSM2
            SEND_PpToSwcFD02Rx_GenericFailSts_FD02_CADM2: accessed-variable=PpToSwcFD02Rx.GenericFailSts_FD02_CADM2
            SEND_PpToSwcFD02Rx_GenericFailSts_FD02_EPS: accessed-variable=PpToSwcFD02Rx.GenericFailSts_FD02_EPS
            SEND_PpToSwcFD02Rx_GenericFailSts_FD02_ORC: accessed-variable=PpToSwcFD02Rx.GenericFailSts_FD02_ORC
            SEND_PpToSwcFD02Rx_GenericFailSts_FD02_SGW: accessed-variable=PpToSwcFD02Rx.GenericFailSts_FD02_SGW
            SEND_PpToSwcFD02Rx_GenericFailSts_FD02_TRLR_REV: accessed-variable=PpToSwcFD02Rx.GenericFailSts_FD02_TRLR_REV
            SEND_PpToSwcFD02Rx_GenericFailSts_FD03_BCM: accessed-variable=PpToSwcFD02Rx.GenericFailSts_FD03_BCM
            SEND_PpToSwcFD02Rx_GenericFailSts_FD03_SGW: accessed-variable=PpToSwcFD02Rx.GenericFailSts_FD03_SGW
            SEND_PpToSwcFD02Rx_GenericFailSts_FD04_BCM: accessed-variable=PpToSwcFD02Rx.GenericFailSts_FD04_BCM
            SEND_PpToSwcFD02Rx_GenericFailSts_FD08_SGW: accessed-variable=PpToSwcFD02Rx.GenericFailSts_FD08_SGW
            SEND_PpToSwcFD02Rx_GenericFailSts_FD11_SGW: accessed-variable=PpToSwcFD02Rx.GenericFailSts_FD11_SGW
            SEND_PpToSwcFD02Rx_Heading_Angle_C2: accessed-variable=PpToSwcFD02Rx.Heading_Angle_C2
            SEND_PpToSwcFD02Rx_IgnitionOnCounter: accessed-variable=PpToSwcFD02Rx.IgnitionOnCounter
            SEND_PpToSwcFD02Rx_LHFWheelSpeed: accessed-variable=PpToSwcFD02Rx.LHFWheelSpeed
            SEND_PpToSwcFD02Rx_LHF_FastPulseCounter: accessed-variable=PpToSwcFD02Rx.LHF_FastPulseCounter
            SEND_PpToSwcFD02Rx_LHF_Spin: accessed-variable=PpToSwcFD02Rx.LHF_Spin
            SEND_PpToSwcFD02Rx_LHRWheelSpeed: accessed-variable=PpToSwcFD02Rx.LHRWheelSpeed
            SEND_PpToSwcFD02Rx_LHR_FastPulseCounter: accessed-variable=PpToSwcFD02Rx.LHR_FastPulseCounter
            SEND_PpToSwcFD02Rx_LHR_Spin: accessed-variable=PpToSwcFD02Rx.LHR_Spin
            SEND_PpToSwcFD02Rx_LatAccelerationOffset_BSM: accessed-variable=PpToSwcFD02Rx.LatAccelerationOffset_BSM
            SEND_PpToSwcFD02Rx_LatAcceleration_C2: accessed-variable=PpToSwcFD02Rx.LatAcceleration_C2
            SEND_PpToSwcFD02Rx_Latitude_RMSE_C2: accessed-variable=PpToSwcFD02Rx.Latitude_RMSE_C2
            SEND_PpToSwcFD02Rx_LongAccelerationOffset_BSM: accessed-variable=PpToSwcFD02Rx.LongAccelerationOffset_BSM
            SEND_PpToSwcFD02Rx_LongAcceleration_C2: accessed-variable=PpToSwcFD02Rx.LongAcceleration_C2
            SEND_PpToSwcFD02Rx_Longitude_RMSE_C2: accessed-variable=PpToSwcFD02Rx.Longitude_RMSE_C2
            SEND_PpToSwcFD02Rx_OperationalModeSts: accessed-variable=PpToSwcFD02Rx.OperationalModeSts
            SEND_PpToSwcFD02Rx_PitchRate_C2: accessed-variable=PpToSwcFD02Rx.PitchRate_C2
            SEND_PpToSwcFD02Rx_Pitch_RMSE_C2: accessed-variable=PpToSwcFD02Rx.Pitch_RMSE_C2
            SEND_PpToSwcFD02Rx_PreviousCanNMState_FD01_BCM: accessed-variable=PpToSwcFD02Rx.PreviousCanNMState_FD01_BCM
            SEND_PpToSwcFD02Rx_PreviousCanNMState_FD01_SGW: accessed-variable=PpToSwcFD02Rx.PreviousCanNMState_FD01_SGW
            SEND_PpToSwcFD02Rx_PreviousCanNMState_FD02_BCM: accessed-variable=PpToSwcFD02Rx.PreviousCanNMState_FD02_BCM
            SEND_PpToSwcFD02Rx_PreviousCanNMState_FD02_BSM2: accessed-variable=PpToSwcFD02Rx.PreviousCanNMState_FD02_BSM2
            SEND_PpToSwcFD02Rx_PreviousCanNMState_FD02_CADM2: accessed-variable=PpToSwcFD02Rx.PreviousCanNMState_FD02_CADM2
            SEND_PpToSwcFD02Rx_PreviousCanNMState_FD02_EPS: accessed-variable=PpToSwcFD02Rx.PreviousCanNMState_FD02_EPS
            SEND_PpToSwcFD02Rx_PreviousCanNMState_FD02_ORC: accessed-variable=PpToSwcFD02Rx.PreviousCanNMState_FD02_ORC
            SEND_PpToSwcFD02Rx_PreviousCanNMState_FD02_SGW: accessed-variable=PpToSwcFD02Rx.PreviousCanNMState_FD02_SGW
            SEND_PpToSwcFD02Rx_PreviousCanNMState_FD02_TRLR_REV: accessed-variable=PpToSwcFD02Rx.PreviousCanNMState_FD02_TRLR_REV
            SEND_PpToSwcFD02Rx_PreviousCanNMState_FD03_BCM: accessed-variable=PpToSwcFD02Rx.PreviousCanNMState_FD03_BCM
            SEND_PpToSwcFD02Rx_PreviousCanNMState_FD03_SGW: accessed-variable=PpToSwcFD02Rx.PreviousCanNMState_FD03_SGW
            SEND_PpToSwcFD02Rx_PreviousCanNMState_FD04_BCM: accessed-variable=PpToSwcFD02Rx.PreviousCanNMState_FD04_BCM
            SEND_PpToSwcFD02Rx_PreviousCanNMState_FD08_SGW: accessed-variable=PpToSwcFD02Rx.PreviousCanNMState_FD08_SGW
            SEND_PpToSwcFD02Rx_PreviousCanNMState_FD11_SGW: accessed-variable=PpToSwcFD02Rx.PreviousCanNMState_FD11_SGW
            SEND_PpToSwcFD02Rx_REF_VEH_SPEED: accessed-variable=PpToSwcFD02Rx.REF_VEH_SPEED
            SEND_PpToSwcFD02Rx_RHFWheelSpeed: accessed-variable=PpToSwcFD02Rx.RHFWheelSpeed
            SEND_PpToSwcFD02Rx_RHF_FastPulseCounter: accessed-variable=PpToSwcFD02Rx.RHF_FastPulseCounter
            SEND_PpToSwcFD02Rx_RHF_Spin: accessed-variable=PpToSwcFD02Rx.RHF_Spin
            SEND_PpToSwcFD02Rx_RHRWheelSpeed: accessed-variable=PpToSwcFD02Rx.RHRWheelSpeed
            SEND_PpToSwcFD02Rx_RHR_FastPulseCounter: accessed-variable=PpToSwcFD02Rx.RHR_FastPulseCounter
            SEND_PpToSwcFD02Rx_RHR_Spin: accessed-variable=PpToSwcFD02Rx.RHR_Spin
            SEND_PpToSwcFD02Rx_RemStActvSts: accessed-variable=PpToSwcFD02Rx.RemStActvSts
            SEND_PpToSwcFD02Rx_RollRate_C2: accessed-variable=PpToSwcFD02Rx.RollRate_C2
            SEND_PpToSwcFD02Rx_Roll_RMSE_C2: accessed-variable=PpToSwcFD02Rx.Roll_RMSE_C2
            SEND_PpToSwcFD02Rx_SBR1RowDriverSeatSts: accessed-variable=PpToSwcFD02Rx.SBR1RowDriverSeatSts
            SEND_PpToSwcFD02Rx_StayActiveSource_FD01_BCM: accessed-variable=PpToSwcFD02Rx.StayActiveSource_FD01_BCM
            SEND_PpToSwcFD02Rx_StayActiveSource_FD01_SGW: accessed-variable=PpToSwcFD02Rx.StayActiveSource_FD01_SGW
            SEND_PpToSwcFD02Rx_StayActiveSource_FD02_BCM: accessed-variable=PpToSwcFD02Rx.StayActiveSource_FD02_BCM
            SEND_PpToSwcFD02Rx_StayActiveSource_FD02_BSM2: accessed-variable=PpToSwcFD02Rx.StayActiveSource_FD02_BSM2
            SEND_PpToSwcFD02Rx_StayActiveSource_FD02_CADM2: accessed-variable=PpToSwcFD02Rx.StayActiveSource_FD02_CADM2
            SEND_PpToSwcFD02Rx_StayActiveSource_FD02_EPS: accessed-variable=PpToSwcFD02Rx.StayActiveSource_FD02_EPS
            SEND_PpToSwcFD02Rx_StayActiveSource_FD02_ORC: accessed-variable=PpToSwcFD02Rx.StayActiveSource_FD02_ORC
            SEND_PpToSwcFD02Rx_StayActiveSource_FD02_SGW: accessed-variable=PpToSwcFD02Rx.StayActiveSource_FD02_SGW
            SEND_PpToSwcFD02Rx_StayActiveSource_FD02_TRLR_REV: accessed-variable=PpToSwcFD02Rx.StayActiveSource_FD02_TRLR_REV
            SEND_PpToSwcFD02Rx_StayActiveSource_FD03_BCM: accessed-variable=PpToSwcFD02Rx.StayActiveSource_FD03_BCM
            SEND_PpToSwcFD02Rx_StayActiveSource_FD03_SGW: accessed-variable=PpToSwcFD02Rx.StayActiveSource_FD03_SGW
            SEND_PpToSwcFD02Rx_StayActiveSource_FD04_BCM: accessed-variable=PpToSwcFD02Rx.StayActiveSource_FD04_BCM
            SEND_PpToSwcFD02Rx_StayActiveSource_FD08_SGW: accessed-variable=PpToSwcFD02Rx.StayActiveSource_FD08_SGW
            SEND_PpToSwcFD02Rx_StayActiveSource_FD11_SGW: accessed-variable=PpToSwcFD02Rx.StayActiveSource_FD11_SGW
            SEND_PpToSwcFD02Rx_TRSC_CenterBtn_Sts: accessed-variable=PpToSwcFD02Rx.TRSC_CenterBtn_Sts
            SEND_PpToSwcFD02Rx_TRSC_EnableBtn_Sts: accessed-variable=PpToSwcFD02Rx.TRSC_EnableBtn_Sts
            SEND_PpToSwcFD02Rx_TRSC_RawKnob: accessed-variable=PpToSwcFD02Rx.TRSC_RawKnob
            SEND_PpToSwcFD02Rx_TotalOdometer: accessed-variable=PpToSwcFD02Rx.TotalOdometer
            SEND_PpToSwcFD02Rx_TurnIndicatorSts: accessed-variable=PpToSwcFD02Rx.TurnIndicatorSts
            SEND_PpToSwcFD02Rx_VehicleStandStillSts: accessed-variable=PpToSwcFD02Rx.VehicleStandStillSts
            SEND_PpToSwcFD02Rx_VerticalAcceleration_C2: accessed-variable=PpToSwcFD02Rx.VerticalAcceleration_C2
            SEND_PpToSwcFD02Rx_WakeupSource_FD01_ADCM: accessed-variable=PpToSwcFD02Rx.WakeupSource_FD01_ADCM
            SEND_PpToSwcFD02Rx_WakeupSource_FD01_BCM: accessed-variable=PpToSwcFD02Rx.WakeupSource_FD01_BCM
            SEND_PpToSwcFD02Rx_WakeupSource_FD01_SGW: accessed-variable=PpToSwcFD02Rx.WakeupSource_FD01_SGW
            SEND_PpToSwcFD02Rx_WakeupSource_FD02_BCM: accessed-variable=PpToSwcFD02Rx.WakeupSource_FD02_BCM
            SEND_PpToSwcFD02Rx_WakeupSource_FD02_BSM2: accessed-variable=PpToSwcFD02Rx.WakeupSource_FD02_BSM2
            SEND_PpToSwcFD02Rx_WakeupSource_FD02_CADM2: accessed-variable=PpToSwcFD02Rx.WakeupSource_FD02_CADM2
            SEND_PpToSwcFD02Rx_WakeupSource_FD02_EPS: accessed-variable=PpToSwcFD02Rx.WakeupSource_FD02_EPS
            SEND_PpToSwcFD02Rx_WakeupSource_FD02_ORC: accessed-variable=PpToSwcFD02Rx.WakeupSource_FD02_ORC
            SEND_PpToSwcFD02Rx_WakeupSource_FD02_SGW: accessed-variable=PpToSwcFD02Rx.WakeupSource_FD02_SGW
            SEND_PpToSwcFD02Rx_WakeupSource_FD02_TRLR_REV: accessed-variable=PpToSwcFD02Rx.WakeupSource_FD02_TRLR_REV
            SEND_PpToSwcFD02Rx_WakeupSource_FD03_BCM: accessed-variable=PpToSwcFD02Rx.WakeupSource_FD03_BCM
            SEND_PpToSwcFD02Rx_WakeupSource_FD03_SGW: accessed-variable=PpToSwcFD02Rx.WakeupSource_FD03_SGW
            SEND_PpToSwcFD02Rx_WakeupSource_FD04_BCM: accessed-variable=PpToSwcFD02Rx.WakeupSource_FD04_BCM
            SEND_PpToSwcFD02Rx_WakeupSource_FD08_SGW: accessed-variable=PpToSwcFD02Rx.WakeupSource_FD08_SGW
            SEND_PpToSwcFD02Rx_WakeupSource_FD11_SGW: accessed-variable=PpToSwcFD02Rx.WakeupSource_FD11_SGW
            SEND_PpToSwcFD02Rx_YawRate_C2: accessed-variable=PpToSwcFD02Rx.YawRate_C2
            SEND_PpToSwcFD02Rx_YawRate_RMSE_C2: accessed-variable=PpToSwcFD02Rx.YawRate_RMSE_C2
            SEND_PpToSwcFD14Rx_FD14_Accel_Pedal_Override: accessed-variable=PpToSwcFD14Rx.FD14_Accel_Pedal_Override
            SEND_PpToSwcFD14Rx_FD14_DriverReq_AxleTrq_Enabled_BSM: accessed-variable=PpToSwcFD14Rx.FD14_DriverReq_AxleTrq_Enabled_BSM
            SEND_PpToSwcFD14Rx_FD14_PPPA_TrqEnblRq_Allowed: accessed-variable=PpToSwcFD14Rx.FD14_PPPA_TrqEnblRq_Allowed
            SEND_PpVcanRxQM_ME_VehInp_to_IpcSignals_QM_t: accessed-variable=PpVcanRxQM.ME_VehInp_to_IpcSignals_QM_t
            SEND_PpBusOffIndication_V_BusOffIndicationFlagRte_u8: accessed-variable=PpBusOffIndication.V_BusOffIndicationFlagRte_u8
        4 x sync call:
          SC_RpE2EServices_ME_E2E_Check: operation=RpE2EServices.ME_E2E_Check
          SC_RpError_CS_B_ReportErrorStatus1_0_B: operation=RpError_CS_B.ReportErrorStatus1_0_B
          SC_RpError_CS_QM_ReportErrorStatus1_0_QM: operation=RpError_CS_QM.ReportErrorStatus1_0_QM
          SC_RpIpcTxData_IPC_Write_v: operation=RpIpcTxData.IPC_Write_v
  swc implementation SWC_VCANRx_Implementation: behavior=SWC_VCANRx_InternalBehavior
